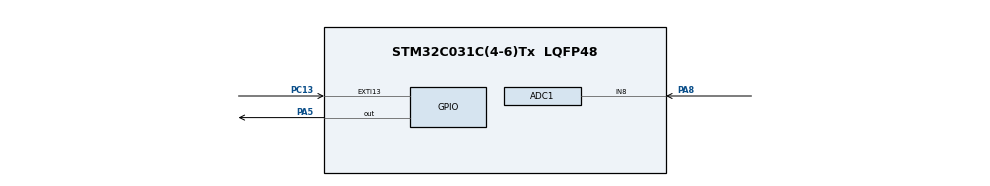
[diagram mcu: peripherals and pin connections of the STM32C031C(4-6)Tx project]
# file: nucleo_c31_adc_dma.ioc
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ADC1.Channel-0\#ChannelRegularConversion=ADC_CHANNEL_8
ADC1.Channel-1\#ChannelRegularConversion=ADC_CHANNEL_VREFINT
ADC1.Channel-2\#ChannelRegularConversion=ADC_CHANNEL_TEMPSENSOR
ADC1.ClockPrescaler=ADC_CLOCK_ASYNC_DIV32
ADC1.EOCSelection=ADC_EOC_SEQ_CONV
ADC1.NbrOfConversion=3
ADC1.NbrOfConversionFlag=1
ADC1.Rank-0\#ChannelRegularConversion=1
ADC1.Rank-1\#ChannelRegularConversion=2
ADC1.Rank-2\#ChannelRegularConversion=3
ADC1.SamplingTime-0\#ChannelRegularConversion=ADC_SAMPLINGTIME_COMMON_1
ADC1.SamplingTime-1\#ChannelRegularConversion=ADC_SAMPLINGTIME_COMMON_1
ADC1.SamplingTime-2\#ChannelRegularConversion=ADC_SAMPLINGTIME_COMMON_1
ADC1.SamplingTimeCommon1=ADC_SAMPLETIME_160CYCLES_5
ADC1.SelectedChannel=ADC_CHANNEL_TEMPSENSOR|ADC_CHANNEL_VREFINT|ADC_CHANNEL_8
ADC1.master=1
Dma.ADC1.0.Direction=DMA_PERIPH_TO_MEMORY
Dma.ADC1.0.EventEnable=DISABLE
Dma.ADC1.0.Instance=DMA1_Channel1
Dma.ADC1.0.MemDataAlignment=DMA_MDATAALIGN_WORD
Dma.ADC1.0.MemInc=DMA_MINC_ENABLE
Dma.ADC1.0.Mode=DMA_NORMAL
Dma.ADC1.0.PeriphDataAlignment=DMA_PDATAALIGN_WORD
Dma.ADC1.0.PeriphInc=DMA_PINC_DISABLE
Dma.ADC1.0.Polarity=HAL_DMAMUX_REQ_GEN_RISING
Dma.ADC1.0.Priority=DMA_PRIORITY_LOW
Dma.ADC1.0.RequestNumber=1
Dma.ADC1.0.SignalID=NONE
Dma.ADC1.0.SyncEnable=DISABLE
Dma.ADC1.0.SyncPolarity=HAL_DMAMUX_SYNC_NO_EVENT
Dma.ADC1.0.SyncRequestNumber=1
Dma.ADC1.0.SyncSignalID=NONE
Dma.Request0=ADC1
Mcu.Family=STM32C0
Mcu.Name=STM32C031C(4-6)Tx
Mcu.Package=LQFP48
NUCLEO-C031C6.BUTTON=1
NUCLEO-C031C6.LD4=true
NUCLEO-C031C6.VCP=true
NVIC.ADC1_IRQn=true\:0\:0\:false\:false\:true\:true\:true\:true
NVIC.DMA1_Channel1_IRQn=true\:0\:0\:false\:false\:true\:false\:true\:true
NVIC.EXTI4_15_IRQn=true\:0\:0\:false\:false\:true\:true\:true\:true
PA13.Signal=DEBUG_SWDIO
PA14-BOOT0.Signal=DEBUG_SWCLK
PA5.Signal=GPIO_Output
PA8.Mode=IN8
PA8.Signal=ADC1_IN8
PB8.Signal=I2C1_SCL
PB9.Signal=I2C1_SDA
PC13.Signal=GPXTI13
PC14-OSCX_IN\ (PC14).Mode=LSE-External-Oscillator
PC14-OSCX_IN\ (PC14).Signal=RCC_OSCX_IN
PC15-OSCX_OUT\ (PC15).Mode=LSE-External-Oscillator
PC15-OSCX_OUT\ (PC15).Signal=RCC_OSCX_OUT
PF0-OSC_IN\ (PF0).Mode=HSE-External-Oscillator
PF0-OSC_IN\ (PF0).Signal=RCC_OSC_IN
PF1-OSC_OUT\ (PF1).Mode=HSE-External-Oscillator
PF1-OSC_OUT\ (PF1).Signal=RCC_OSC_OUT
ProjectManager.HeapSize=0x200
ProjectManager.StackSize=0x400
ProjectManager.TargetToolchain=STM32CubeIDE
RCC.ADCFreq_Value=48000000
RCC.AHBFreq_Value=48000000
RCC.CortexFreq_Value=48000000
RCC.EXTERNAL_CLOCK_VALUE=12288000
RCC.HCLKFreq_Value=48000000
RCC.HSE_VALUE=48000000
RCC.HSISYSCLKDivider=RCC_HSI_DIV1
RCC.HSI_VALUE=48000000
RCC.SYSCLKFreq_VALUE=48000000
RCC.SYSCLKSource=RCC_SYSCLKSOURCE_HSE
VP_ADC1_TempSens_Input.Mode=IN-TempSens
VP_ADC1_Vref_Input.Mode=IN-Vrefint
VP_NUCLEO-C031C6_VS_BSP_COMMON.Mode=COMMON
board=NUCLEO-C031C6

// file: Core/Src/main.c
/* USER CODE BEGIN Header */
/**
  ******************************************************************************
  * @file           : main.c
  * @brief          : Main program body
  ******************************************************************************
  * @attention
  *
  * Copyright (c) 2024 STMicroelectronics.
  * All rights reserved.
  *
  * This software is licensed under terms that can be found in the LICENSE file
  * in the root directory of this software component.
  * If no LICENSE file comes with this software, it is provided AS-IS.
  *
  ******************************************************************************
  */
/* USER CODE END Header */
#include "main.h"

/* USER CODE BEGIN Includes */

#include <string.h>

/* USER CODE END Includes */

/* USER CODE BEGIN PM */

/* Definitions of internal temperature sensor */
#define INTERNAL_TEMPSENSOR_AVGSLOPE   ((int32_t) 2530)        /* Internal temperature sensor, parameter Avg_Slope (unit: uV/DegCelsius). Refer to device datasheet for min/typ/max values. */
#define INTERNAL_TEMPSENSOR_V30        ((((int32_t)*TEMPSENSOR_CAL1_ADDR) \
                                        * TEMPSENSOR_CAL_VREFANALOG) / __LL_ADC_DIGITAL_SCALE(LL_ADC_RESOLUTION_12B)) /* Internal temperature sensor, parameter V30 (unit: mV), using calibration data (alternate solution possible with datasheet parameter: V30=760mV typ for STM32C0) */
#define INTERNAL_TEMPSENSOR_V30_TEMP   (TEMPSENSOR_CAL1_TEMP)

/* USER CODE END PM */

COM_InitTypeDef BspCOMInit;
ADC_HandleTypeDef hadc1;
DMA_HandleTypeDef hdma_adc1;

void SystemClock_Config(void);
static void MX_GPIO_Init(void);
static void MX_DMA_Init(void);
static void MX_ADC1_Init(void);

/* USER CODE BEGIN 0 */

static char uart_tx_data[512];
__IO uint32_t adc_data[3];

/* USER CODE END 0 */

int main(void)
{

  /* MCU Configuration--------------------------------------------------------*/

  /* Reset of all peripherals, Initializes the Flash interface and the Systick. */
  HAL_Init();

  /* Configure the system clock */
  SystemClock_Config();

  /* Initialize all configured peripherals */
  MX_GPIO_Init();
  MX_DMA_Init();
  MX_ADC1_Init();

  /* Initialize leds */
  BSP_LED_Init(LED_GREEN);

  /* Initialize USER push-button, will be used to trigger an interrupt each time it's pressed.*/
  BSP_PB_Init(BUTTON_USER, BUTTON_MODE_EXTI);

  /* Initialize COM1 port (115200, 8 bits (7-bit data + 1 stop bit), no parity */
  BspCOMInit.BaudRate   = 115200;
  BspCOMInit.WordLength = COM_WORDLENGTH_8B;
  BspCOMInit.StopBits   = COM_STOPBITS_1;
  BspCOMInit.Parity     = COM_PARITY_NONE;
  BspCOMInit.HwFlowCtl  = COM_HWCONTROL_NONE;
  if (BSP_COM_Init(COM1, &BspCOMInit) != BSP_ERROR_NONE)
  {
    Error_Handler();
  }

  /* Infinite loop */
  /* USER CODE BEGIN WHILE */

  /* Run the ADC calibration in single-ended mode */
  if (HAL_ADCEx_Calibration_Start(&hadc1) != HAL_OK)
  {
    /* Calibration Error */
    Error_Handler();
  }

  while (1)
  {
    while (LL_ADC_REG_IsConversionOngoing(hadc1.Instance)) {}

    /* Start ADC group regular conversion with DMA */
    if (HAL_ADC_Start_DMA(&hadc1, (uint32_t *)adc_data, 3u) != HAL_OK)
    {
      /* ADC conversion start error */
      Error_Handler();
    }

    BSP_LED_Toggle(LED_GREEN);
    HAL_Delay(400);

    /* USER CODE END WHILE */

  }
}

void SystemClock_Config(void)
{
  RCC_OscInitTypeDef RCC_OscInitStruct = {0};
  RCC_ClkInitTypeDef RCC_ClkInitStruct = {0};

  /** Initializes the RCC Oscillators according to the specified parameters
  * in the RCC_OscInitTypeDef structure.
  */
  RCC_OscInitStruct.OscillatorType = RCC_OSCILLATORTYPE_HSE;
  RCC_OscInitStruct.HSEState = RCC_HSE_ON;
  if (HAL_RCC_OscConfig(&RCC_OscInitStruct) != HAL_OK)
  {
    Error_Handler();
  }

  /** Initializes the CPU, AHB and APB buses clocks
  */
  RCC_ClkInitStruct.ClockType = RCC_CLOCKTYPE_HCLK|RCC_CLOCKTYPE_SYSCLK
                              |RCC_CLOCKTYPE_PCLK1;
  RCC_ClkInitStruct.SYSCLKSource = RCC_SYSCLKSOURCE_HSE;
  RCC_ClkInitStruct.SYSCLKDivider = RCC_SYSCLK_DIV1;
  RCC_ClkInitStruct.AHBCLKDivider = RCC_HCLK_DIV1;
  RCC_ClkInitStruct.APB1CLKDivider = RCC_APB1_DIV1;

  if (HAL_RCC_ClockConfig(&RCC_ClkInitStruct, FLASH_LATENCY_1) != HAL_OK)
  {
    Error_Handler();
  }
}

static void MX_ADC1_Init(void)
{

  ADC_ChannelConfTypeDef sConfig = {0};

  /** Configure the global features of the ADC (Clock, Resolution, Data Alignment and number of conversion)
  */
  hadc1.Instance = ADC1;
  hadc1.Init.ClockPrescaler = ADC_CLOCK_ASYNC_DIV32;
  hadc1.Init.Resolution = ADC_RESOLUTION_12B;
  hadc1.Init.DataAlign = ADC_DATAALIGN_RIGHT;
  hadc1.Init.ScanConvMode = ADC_SCAN_ENABLE;
  hadc1.Init.EOCSelection = ADC_EOC_SEQ_CONV;
  hadc1.Init.LowPowerAutoWait = DISABLE;
  hadc1.Init.LowPowerAutoPowerOff = DISABLE;
  hadc1.Init.ContinuousConvMode = DISABLE;
  hadc1.Init.NbrOfConversion = 3;
  hadc1.Init.DiscontinuousConvMode = DISABLE;
  hadc1.Init.ExternalTrigConv = ADC_SOFTWARE_START;
  hadc1.Init.ExternalTrigConvEdge = ADC_EXTERNALTRIGCONVEDGE_NONE;
  hadc1.Init.DMAContinuousRequests = DISABLE;
  hadc1.Init.Overrun = ADC_OVR_DATA_PRESERVED;
  hadc1.Init.SamplingTimeCommon1 = ADC_SAMPLETIME_160CYCLES_5;
  hadc1.Init.SamplingTimeCommon2 = ADC_SAMPLETIME_1CYCLE_5;
  hadc1.Init.OversamplingMode = DISABLE;
  hadc1.Init.TriggerFrequencyMode = ADC_TRIGGER_FREQ_HIGH;
  if (HAL_ADC_Init(&hadc1) != HAL_OK)
  {
    Error_Handler();
  }

  /** Configure Regular Channel
  */
  sConfig.Channel = ADC_CHANNEL_8;
  sConfig.Rank = ADC_REGULAR_RANK_1;
  sConfig.SamplingTime = ADC_SAMPLINGTIME_COMMON_1;
  if (HAL_ADC_ConfigChannel(&hadc1, &sConfig) != HAL_OK)
  {
    Error_Handler();
  }

  /** Configure Regular Channel
  */
  sConfig.Channel = ADC_CHANNEL_VREFINT;
  sConfig.Rank = ADC_REGULAR_RANK_2;
  if (HAL_ADC_ConfigChannel(&hadc1, &sConfig) != HAL_OK)
  {
    Error_Handler();
  }

  /** Configure Regular Channel
  */
  sConfig.Channel = ADC_CHANNEL_TEMPSENSOR;
  sConfig.Rank = ADC_REGULAR_RANK_3;
  if (HAL_ADC_ConfigChannel(&hadc1, &sConfig) != HAL_OK)
  {
    Error_Handler();
  }

}

static void MX_DMA_Init(void)
{

  /* DMA controller clock enable */
  __HAL_RCC_DMA1_CLK_ENABLE();

  /* DMA interrupt init */
  /* DMA1_Channel1_IRQn interrupt configuration */
  HAL_NVIC_SetPriority(DMA1_Channel1_IRQn, 0, 0);
  HAL_NVIC_EnableIRQ(DMA1_Channel1_IRQn);

}

static void MX_GPIO_Init(void)
{
  GPIO_InitTypeDef GPIO_InitStruct = {0};

  /* GPIO Ports Clock Enable */
  __HAL_RCC_GPIOC_CLK_ENABLE();
  __HAL_RCC_GPIOF_CLK_ENABLE();
  __HAL_RCC_GPIOA_CLK_ENABLE();
  __HAL_RCC_GPIOB_CLK_ENABLE();

  /*Configure GPIO pins : PB8 PB9 */
  GPIO_InitStruct.Pin = GPIO_PIN_8|GPIO_PIN_9;
  GPIO_InitStruct.Mode = GPIO_MODE_AF_OD;
  GPIO_InitStruct.Pull = GPIO_NOPULL;
  GPIO_InitStruct.Speed = GPIO_SPEED_FREQ_LOW;
  GPIO_InitStruct.Alternate = GPIO_AF6_I2C1;
  HAL_GPIO_Init(GPIOB, &GPIO_InitStruct);

}

/* USER CODE BEGIN 4 */

/**
  * @brief  Conversion complete callback in non-blocking mode.
  * @param hadc ADC handle
  * @retval None
  */
void HAL_ADC_ConvCpltCallback(ADC_HandleTypeDef *hadc)
{
  /* Prevent unused argument(s) compilation warning */
  UNUSED(hadc);

  static uint32_t idx_conv = 0ul;

  sprintf(uart_tx_data, "\n\r# %ld\n\r", idx_conv++);
  HAL_UART_Transmit(hcom_uart, (uint8_t*)uart_tx_data, strlen(uart_tx_data), 100);

  uint32_t vref_mv = __HAL_ADC_CALC_VREFANALOG_VOLTAGE(adc_data[1], ADC_RESOLUTION_12B);
  sprintf(uart_tx_data, "Vref [mV] %ld\n\r", vref_mv);
  HAL_UART_Transmit(hcom_uart, (uint8_t*)uart_tx_data, strlen(uart_tx_data), 100);

  uint32_t vin8_mv = __HAL_ADC_CALC_DATA_TO_VOLTAGE(vref_mv, adc_data[0], ADC_RESOLUTION_12B);
  sprintf(uart_tx_data, "IN8 [mV] %ld\n\r", vin8_mv);
  HAL_UART_Transmit(hcom_uart, (uint8_t*)uart_tx_data, strlen(uart_tx_data), 100);

  uint32_t temp_c = __LL_ADC_CALC_TEMPERATURE_TYP_PARAMS(INTERNAL_TEMPSENSOR_AVGSLOPE,
                                                          INTERNAL_TEMPSENSOR_V30,
                                                          INTERNAL_TEMPSENSOR_V30_TEMP,
                                                          vref_mv,
                                                          adc_data[2],
                                                          LL_ADC_RESOLUTION_12B);
  sprintf(uart_tx_data, "Temperature [deg.C] %ld\n\r", temp_c);
  HAL_UART_Transmit(hcom_uart, (uint8_t*)uart_tx_data, strlen(uart_tx_data), 100);
}

/* USER CODE END 4 */

void Error_Handler(void)
{
  __disable_irq();
  while (1)
  {
  }
}
